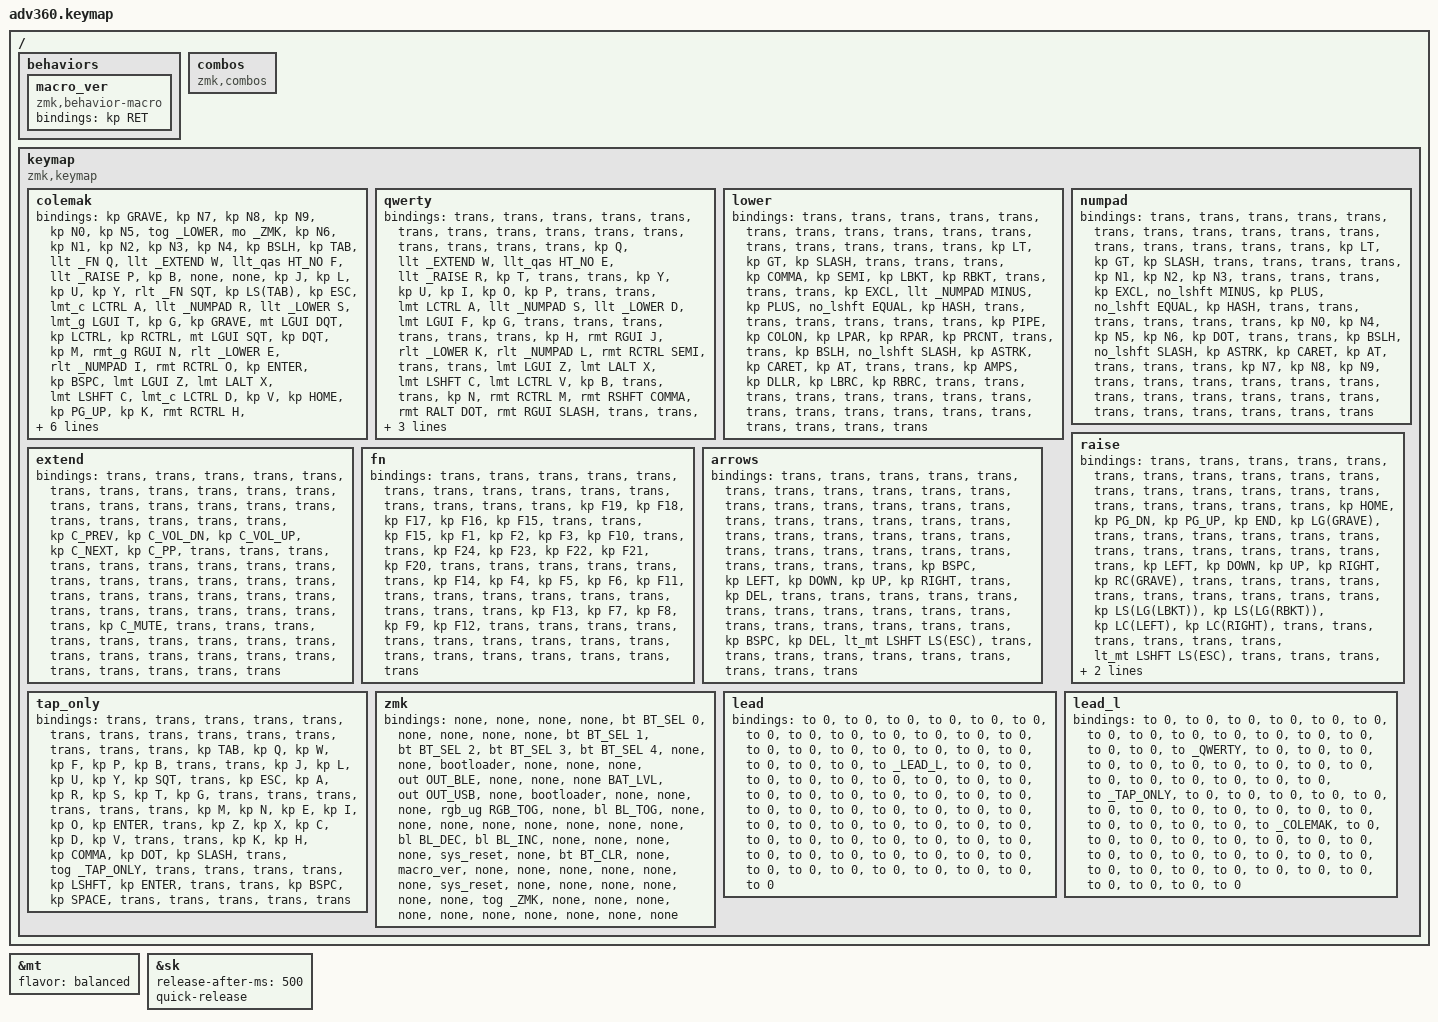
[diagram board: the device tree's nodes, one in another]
#include <behaviors.dtsi>
#include <dt-bindings/zmk/keys.h>
#include <dt-bindings/zmk/bt.h>
#include <dt-bindings/zmk/rgb.h>
#include <dt-bindings/zmk/backlight.h>

#include "layers.dtsi"
#include <dt-bindings/zmk/outputs.h>


// RGB Underglow command for the current battery level on each side
#define BAT_LVL &rgb_ug RGB_MEFS_CMD 5


// Built-in Behavior tweaks
&mt {
  flavor = "balanced";
};
&sk {
  release-after-ms = <500>;
  // deactivate sticky key on next key press, instead of next key release
  quick-release;
};


/ {
    behaviors {
      #include "macros.dtsi"
      #include "version.dtsi"
      #ifndef VERSION_MACRO
      macro_ver: macro_ver {
        compatible = "zmk,behavior-macro";
        #binding-cells = <0>;
        bindings = <&kp RET>;
      };
      #endif

      #include "hold_tap.dtsi"
    };

    combos {
      compatible = "zmk,combos";
      #include "combos.dtsi"
    };

  keymap {
    compatible = "zmk,keymap";

    // TODO: Add macros like you have in QMK for the keymap bindings L/R hands and rows
    // TODO: add curly single and double quote symbols somewhere in the keymap
    // TODO: See if a layer without any mod-tap keys will work at the MacOS
    // filevault login screen
    colemak {
      bindings = <
        /* LH */ &kp GRAVE       &kp N7          &kp N8          &kp N9            &kp N0          &kp N5  &tog _LOWER                                      /* RH */                           &mo _ZMK              &kp N6  &kp N1         &kp N2            &kp N3          &kp N4           &kp BSLH
        /* LH */ &kp TAB         &llt _FN Q      &llt _EXTEND W  &llt_qas HT_NO F  &llt _RAISE P   &kp B   &none                                            /* RH */                           &none                 &kp J   &kp L          &kp U             &kp Y           &rlt _FN SQT     &kp LS(TAB)
        /* LH */ &kp ESC         &lmt_c LCTRL A  &llt _NUMPAD R  &llt _LOWER S     &lmt_g LGUI T   &kp G   &kp GRAVE         &mt LGUI DQT        &kp LCTRL  /* RH */  &kp RCTRL  &mt LGUI SQT  &kp DQT               &kp M   &rmt_g RGUI N  &rlt _LOWER E     &rlt _NUMPAD I  &rmt RCTRL O     &kp ENTER
        /* LH */ &kp BSPC        &lmt LGUI Z     &lmt LALT X     &lmt LSHFT C      &lmt_c LCTRL D  &kp V                                         &kp HOME   /* RH */  &kp PG_UP                                      &kp K   &rmt RCTRL H   &rmt RSHFT COMMA  &rmt RALT DOT   &rmt RGUI SLASH  &kp DEL
        /* LH */ &tog _TAP_ONLY  &kp PG_UP       &kp PG_DN       &kp LEFT          &kp RIGHT               &lt_mt LSHFT ESC  &lt_lt _NUMPAD DEL  &kp TAB    /* RH */  &kp TAB    &kp BSPC      &rt_lt _ARROWS SPACE          &kp DOWN       &kp UP            &kp LBKT        &kp RBKT         &mo _LOWER
      >;
    };

    qwerty {
      bindings = <
        /* LH */ &trans  &trans        &trans          &trans            &trans         &trans  &trans                  /* RH */                  &trans  &trans  &trans        &trans            &trans         &trans           &trans
        /* LH */ &trans  &kp Q         &llt _EXTEND W  &llt_qas HT_NO E  &llt _RAISE R  &kp T   &trans                  /* RH */                  &trans  &kp Y   &kp U         &kp I             &kp  O         &kp P            &trans
        /* LH */ &trans  &lmt LCTRL A  &llt _NUMPAD S  &llt _LOWER D     &lmt LGUI F    &kp G   &trans  &trans  &trans  /* RH */  &trans  &trans  &trans  &kp H   &rmt RGUI J   &rlt _LOWER K     &rlt _NUMPAD L &rmt RCTRL SEMI  &trans
        /* LH */ &trans  &lmt LGUI Z   &lmt LALT X     &lmt LSHFT C      &lmt LCTRL V   &kp B                   &trans  /* RH */  &trans                  &kp N   &rmt RCTRL M  &rmt RSHFT COMMA  &rmt RALT DOT  &rmt RGUI SLASH  &trans
        /* LH */ &trans  &trans        &trans          &trans            &trans         &trans  &trans  &trans  &trans  /* RH */  &trans  &trans  &trans  &trans  &trans        &trans            &trans         &trans           &trans
      >;
    };

    lower {
      bindings = <
        /* LH */ &trans  &trans    &trans              &trans     &trans           &trans    &trans                  /* RH */                  &trans  &trans    &trans     &trans    &trans    &trans     &trans
        /* LH */ &trans  &trans    &kp LT              &kp GT     &kp SLASH        &trans    &trans                  /* RH */                  &trans  &kp COMMA &kp SEMI   &kp LBKT  &kp RBKT  &trans     &trans
        /* LH */ &trans  &kp EXCL  &llt _NUMPAD MINUS  &kp PLUS   &no_lshft EQUAL  &kp HASH  &trans  &trans  &trans  /* RH */  &trans  &trans  &trans  &kp PIPE  &kp COLON  &kp LPAR  &kp RPAR  &kp PRCNT  &trans
        /* LH */ &trans  &kp BSLH  &no_lshft SLASH     &kp ASTRK  &kp CARET        &kp AT                    &trans  /* RH */  &trans                  &kp AMPS  &kp DLLR   &kp LBRC  &kp RBRC  &trans     &trans
        /* LH */ &trans  &trans    &trans              &trans     &trans                     &trans  &trans  &trans  /* RH */  &trans  &trans  &trans            &trans     &trans    &trans    &trans     &trans
      >;
    };

    numpad {
      bindings = <
        /* LH */ &trans  &trans    &trans           &trans     &trans           &trans    &trans                  /* RH */                  &trans  &trans  &trans  &trans  &trans  &trans   &trans
        /* LH */ &trans  &trans    &kp LT           &kp GT     &kp SLASH        &trans    &trans                  /* RH */                  &trans  &trans  &kp N1  &kp N2  &kp N3  &trans   &trans
        /* LH */ &trans  &kp EXCL  &no_lshft MINUS  &kp PLUS   &no_lshft EQUAL  &kp HASH  &trans  &trans  &trans  /* RH */  &trans  &trans  &trans  &kp N0  &kp N4  &kp N5  &kp N6  &kp DOT  &trans
        /* LH */ &trans  &kp BSLH  &no_lshft SLASH  &kp ASTRK  &kp CARET        &kp AT                    &trans  /* RH */  &trans                  &trans  &kp N7  &kp N8  &kp N9  &trans   &trans
        /* LH */ &trans  &trans    &trans           &trans     &trans                     &trans  &trans  &trans  /* RH */  &trans  &trans  &trans          &trans  &trans  &trans  &trans   &trans
      >;
    };

    raise {
      bindings = <
        /* LH */ &trans  &trans  &trans  &trans  &trans  &trans  &trans                                /* RH */                  &trans  &trans    &trans            &trans            &trans          &trans            &trans
        /* LH */ &trans  &trans  &trans  &trans  &trans  &trans  &trans                                /* RH */                  &trans  &kp HOME  &kp PG_DN         &kp PG_UP         &kp END         &kp LG(GRAVE)     &trans
        /* LH */ &trans  &trans  &trans  &trans  &trans  &trans  &trans                &trans  &trans  /* RH */  &trans  &trans  &trans  &kp LEFT  &kp DOWN          &kp UP            &kp RIGHT       &kp RC(GRAVE)     &trans
        /* LH */ &trans  &trans  &trans  &trans  &trans  &trans                                &trans  /* RH */  &trans                  &trans    &kp LS(LG(LBKT))  &kp LS(LG(RBKT))  &kp LC(LEFT)    &kp LC(RIGHT)     &trans
        /* LH */ &trans  &trans  &trans  &trans  &trans          &lt_mt LSHFT LS(ESC)  &trans  &trans  /* RH */  &trans  &trans  &trans            &kp LC(PG_UP)     &kp LC(PG_DN)     &kp LC(LA(UP))  &kp LC(LA(DOWN))  &trans
      >;
    };

    extend {
      bindings = <
        /* LH */ &trans  &trans  &trans  &trans  &trans  &trans  &trans                  /* RH */                  &trans  &trans      &trans        &trans        &trans      &trans    &trans
        /* LH */ &trans  &trans  &trans  &trans  &trans  &trans  &trans                  /* RH */                  &trans  &kp C_PREV  &kp C_VOL_DN  &kp C_VOL_UP  &kp C_NEXT  &kp C_PP  &trans
        /* LH */ &trans  &trans  &trans  &trans  &trans  &trans  &trans  &trans  &trans  /* RH */  &trans  &trans  &trans  &trans      &trans        &trans        &trans      &trans    &trans
        /* LH */ &trans  &trans  &trans  &trans  &trans  &trans                  &trans  /* RH */  &trans                  &trans      &kp C_MUTE    &trans        &trans      &trans    &trans
        /* LH */ &trans  &trans  &trans  &trans  &trans          &trans  &trans  &trans  /* RH */  &trans  &trans  &trans              &trans        &trans        &trans      &trans    &trans
      >;
    };

    // TODO: Rearrange these more logically, like with a grid on the left hand also
    fn {
      bindings = <
        /* LH */ &trans  &trans   &trans   &trans   &trans   &trans   &trans                  /* RH */                  &trans  &trans   &trans  &trans  &trans  &trans   &trans
        /* LH */ &trans  &kp F19  &kp F18  &kp F17  &kp F16  &kp F15  &trans                  /* RH */                  &trans  &kp F15  &kp F1  &kp F2  &kp F3  &kp F10  &trans
        /* LH */ &trans  &kp F24  &kp F23  &kp F22  &kp F21  &kp F20  &trans  &trans  &trans  /* RH */  &trans  &trans  &trans  &kp F14  &kp F4  &kp F5  &kp F6  &kp F11  &trans
        /* LH */ &trans  &trans   &trans   &trans   &trans   &trans                   &trans  /* RH */  &trans                  &kp F13  &kp F7  &kp F8  &kp F9  &kp F12  &trans
        /* LH */ &trans  &trans   &trans   &trans   &trans            &trans  &trans  &trans  /* RH */  &trans  &trans  &trans           &trans  &trans  &trans  &trans   &trans
      >;
    };

    arrows {
      bindings = <
        /* LH */ &trans  &trans  &trans  &trans    &trans   &trans  &trans                                /* RH */                  &trans    &trans    &trans    &trans  &trans     &trans  &trans
        /* LH */ &trans  &trans  &trans  &trans    &trans   &trans  &trans                                /* RH */                  &trans    &trans    &trans    &trans  &trans     &trans  &trans
        /* LH */ &trans  &trans  &trans  &trans    &trans   &trans  &trans                &trans  &trans  /* RH */  &trans  &trans  &kp BSPC  &kp LEFT  &kp DOWN  &kp UP  &kp RIGHT  &trans  &kp DEL
        /* LH */ &trans  &trans  &trans  &trans    &trans   &trans                                &trans  /* RH */  &trans                    &trans    &trans    &trans  &trans     &trans  &trans
        /* LH */ &trans  &trans  &trans  &kp BSPC  &kp DEL          &lt_mt LSHFT LS(ESC)  &trans  &trans  /* RH */  &trans  &trans  &trans              &trans    &trans  &trans     &trans  &trans
      >;
    };

    tap_only {
      bindings = <
        /* LH */ &trans          &trans  &trans  &trans  &trans  &trans  &trans                        /* RH */                    &trans     &trans  &trans  &trans     &trans   &trans     &trans
        /* LH */ &kp TAB         &kp Q   &kp W   &kp F   &kp P   &kp B   &trans                        /* RH */                    &trans     &kp J   &kp L   &kp U      &kp Y    &kp SQT    &trans
        /* LH */ &kp ESC         &kp A   &kp R   &kp S   &kp T   &kp G   &trans     &trans     &trans  /* RH */  &trans  &trans    &trans     &kp M   &kp N   &kp E      &kp I    &kp O      &kp ENTER
        /* LH */ &trans          &kp Z   &kp X   &kp C   &kp D   &kp V                         &trans  /* RH */  &trans                       &kp K   &kp H   &kp COMMA  &kp DOT  &kp SLASH  &trans
        /* LH */ &tog _TAP_ONLY  &trans  &trans  &trans  &trans          &kp LSHFT  &kp ENTER  &trans  /* RH */  &trans  &kp BSPC  &kp SPACE          &trans  &trans     &trans   &trans     &trans
      >;
    };

    zmk {
      bindings = <
        /* LH */ &none  &none        &none            &none       &bt BT_SEL 0  &none         &none                    /* RH */                &none   &none  &bt BT_SEL 1  &bt BT_SEL 2  &bt BT_SEL 3  &bt BT_SEL 4  &none
        /* LH */ &none  &bootloader  &none            &none       &none         &out OUT_BLE  &none                    /* RH */                &none   &none  BAT_LVL       &out OUT_USB  &none         &bootloader   &none
        /* LH */ &none  &none        &rgb_ug RGB_TOG  &none       &bl BL_TOG    &none         &none      &none  &none  /* RH */  &none  &none  &none   &none  &bl BL_DEC    &bl BL_INC    &none         &none         &none
        /* LH */ &none  &sys_reset   &none            &bt BT_CLR  &none         &macro_ver                      &none  /* RH */  &none                 &none  &none         &none         &none         &sys_reset    &none
        /* LH */ &none  &none        &none            &none       &none                       &tog _ZMK  &none  &none  /* RH */  &none  &none  &none          &none         &none         &none         &none         &none
      >;
    };

    lead {
      bindings = <
        /* LH */ &to 0  &to 0  &to 0  &to 0  &to 0  &to 0  &to 0                /* RH */                &to 0  &to 0  &to 0        &to 0  &to 0  &to 0  &to 0
        /* LH */ &to 0  &to 0  &to 0  &to 0  &to 0  &to 0  &to 0                /* RH */                &to 0  &to 0  &to _LEAD_L  &to 0  &to 0  &to 0  &to 0
        /* LH */ &to 0  &to 0  &to 0  &to 0  &to 0  &to 0  &to 0  &to 0  &to 0  /* RH */  &to 0  &to 0  &to 0  &to 0  &to 0        &to 0  &to 0  &to 0  &to 0
        /* LH */ &to 0  &to 0  &to 0  &to 0  &to 0  &to 0                &to 0  /* RH */  &to 0                &to 0  &to 0        &to 0  &to 0  &to 0  &to 0
        /* LH */ &to 0  &to 0  &to 0  &to 0  &to 0         &to 0  &to 0  &to 0  /* RH */  &to 0  &to 0  &to 0         &to 0        &to 0  &to 0  &to 0  &to 0
      >;
    };

    lead_l {
      bindings = <
        /* LH */ &to 0  &to 0        &to 0  &to 0         &to 0          &to 0  &to 0                /* RH */                &to 0  &to 0  &to 0  &to 0  &to 0  &to 0  &to 0
        /* LH */ &to 0  &to _QWERTY  &to 0  &to 0         &to 0          &to 0  &to 0                /* RH */                &to 0  &to 0  &to 0  &to 0  &to 0  &to 0  &to 0
        /* LH */ &to 0  &to 0        &to 0  &to 0         &to _TAP_ONLY  &to 0  &to 0  &to 0  &to 0  /* RH */  &to 0  &to 0  &to 0  &to 0  &to 0  &to 0  &to 0  &to 0  &to 0
        /* LH */ &to 0  &to 0        &to 0  &to _COLEMAK  &to 0          &to 0                &to 0  /* RH */  &to 0                &to 0  &to 0  &to 0  &to 0  &to 0  &to 0
        /* LH */ &to 0  &to 0        &to 0  &to 0         &to 0                 &to 0  &to 0  &to 0  /* RH */  &to 0  &to 0  &to 0         &to 0  &to 0  &to 0  &to 0  &to 0
      >;
    };

    // lead_template {
    //   bindings = <
    //     /* LH */ &to 0  &to 0  &to 0  &to 0  &to 0  &to 0  &to 0                /* RH */                &to 0  &to 0  &to 0  &to 0  &to 0  &to 0  &to 0
    //     /* LH */ &to 0  &to 0  &to 0  &to 0  &to 0  &to 0  &to 0                /* RH */                &to 0  &to 0  &to 0  &to 0  &to 0  &to 0  &to 0
    //     /* LH */ &to 0  &to 0  &to 0  &to 0  &to 0  &to 0  &to 0  &to 0  &to 0  /* RH */  &to 0  &to 0  &to 0  &to 0  &to 0  &to 0  &to 0  &to 0  &to 0
    //     /* LH */ &to 0  &to 0  &to 0  &to 0  &to 0  &to 0                &to 0  /* RH */  &to 0                &to 0  &to 0  &to 0  &to 0  &to 0  &to 0
    //     /* LH */ &to 0  &to 0  &to 0  &to 0  &to 0         &to 0  &to 0  &to 0  /* RH */  &to 0  &to 0  &to 0         &to 0  &to 0  &to 0  &to 0  &to 0
    //   >;
    // };

    // template {
    //   bindings = <
    //     /* LH */ &trans  &trans  &trans  &trans  &trans  &trans  &trans                  /* RH */                  &trans  &trans  &trans  &trans  &trans  &trans  &trans
    //     /* LH */ &trans  &trans  &trans  &trans  &trans  &trans  &trans                  /* RH */                  &trans  &trans  &trans  &trans  &trans  &trans  &trans
    //     /* LH */ &trans  &trans  &trans  &trans  &trans  &trans  &trans  &trans  &trans  /* RH */  &trans  &trans  &trans  &trans  &trans  &trans  &trans  &trans  &trans
    //     /* LH */ &trans  &trans  &trans  &trans  &trans  &trans                  &trans  /* RH */  &trans                  &trans  &trans  &trans  &trans  &trans  &trans
    //     /* LH */ &trans  &trans  &trans  &trans  &trans          &trans  &trans  &trans  /* RH */  &trans  &trans  &trans          &trans  &trans  &trans  &trans  &trans
    //   >;
    // };
  };
};
